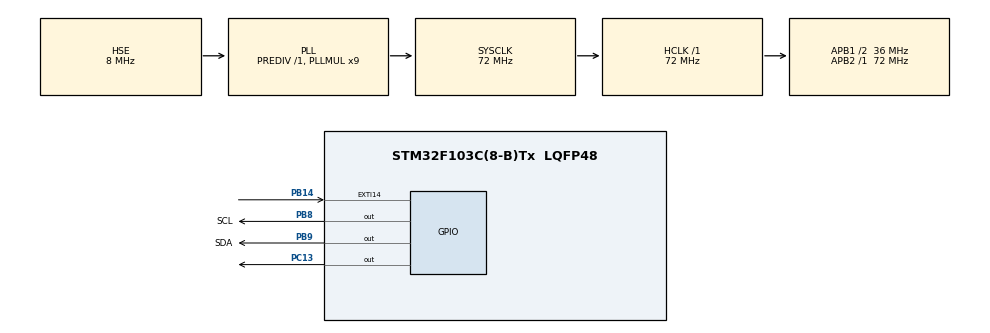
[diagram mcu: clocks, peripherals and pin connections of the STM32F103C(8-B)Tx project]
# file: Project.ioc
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Mcu.Family=STM32F1
Mcu.Name=STM32F103C(8-B)Tx
Mcu.Package=LQFP48
NVIC.EXTI15_10_IRQn=true\:1\:0\:true\:false\:true\:true\:true\:true
NVIC.PriorityGroup=NVIC_PRIORITYGROUP_4
PA13.Mode=Serial_Wire
PA13.Signal=SYS_JTMS-SWDIO
PA14.Mode=Serial_Wire
PA14.Signal=SYS_JTCK-SWCLK
PB14.GPIO_ModeDefaultEXTI=GPIO_MODE_IT_FALLING
PB14.GPIO_PuPd=GPIO_PULLUP
PB14.Signal=GPXTI14
PB8.GPIO_Label=SCL
PB8.GPIO_ModeDefaultOutputPP=GPIO_MODE_OUTPUT_OD
PB8.GPIO_PuPd=GPIO_NOPULL
PB8.GPIO_Speed=GPIO_SPEED_FREQ_HIGH
PB8.PinState=GPIO_PIN_RESET
PB8.Signal=GPIO_Output
PB9.GPIO_Label=SDA
PB9.GPIO_ModeDefaultOutputPP=GPIO_MODE_OUTPUT_OD
PB9.GPIO_PuPd=GPIO_NOPULL
PB9.GPIO_Speed=GPIO_SPEED_FREQ_HIGH
PB9.Signal=GPIO_Output
PC13-TAMPER-RTC.GPIO_PuPd=GPIO_PULLDOWN
PC13-TAMPER-RTC.Signal=GPIO_Output
PD0-OSC_IN.Mode=HSE-External-Oscillator
PD0-OSC_IN.Signal=RCC_OSC_IN
PD1-OSC_OUT.Mode=HSE-External-Oscillator
PD1-OSC_OUT.Signal=RCC_OSC_OUT
ProjectManager.HeapSize=0x200
ProjectManager.StackSize=0x400
ProjectManager.TargetToolchain=MDK-ARM V5.32
RCC.AHBFreq_Value=72000000
RCC.APB1CLKDivider=RCC_HCLK_DIV2
RCC.APB1Freq_Value=36000000
RCC.APB1TimFreq_Value=72000000
RCC.APB2Freq_Value=72000000
RCC.APB2TimFreq_Value=72000000
RCC.HCLKFreq_Value=72000000
RCC.PLLMUL=RCC_PLL_MUL9
RCC.PLLSourceVirtual=RCC_PLLSOURCE_HSE
RCC.SYSCLKFreq_VALUE=72000000
RCC.SYSCLKSource=RCC_SYSCLKSOURCE_PLLCLK
RCC.USBFreq_Value=72000000
board=custom

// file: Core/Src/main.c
/* USER CODE BEGIN Header */
/**
  ******************************************************************************
  * @file           : main.c
  * @brief          : Main program body
  ******************************************************************************
  * @attention
  *
  * Copyright (c) 2025 STMicroelectronics.
  * All rights reserved.
  *
  * This software is licensed under terms that can be found in the LICENSE file
  * in the root directory of this software component.
  * If no LICENSE file comes with this software, it is provided AS-IS.
  *
  ******************************************************************************
  */
/* USER CODE END Header */
#include "main.h"
#include "gpio.h"

/* USER CODE BEGIN Includes */
#include "OLED.h"
#include "CountSensor.h"
/* USER CODE END Includes */

void SystemClock_Config(void);

/* USER CODE BEGIN 0 */

// 滴答定时器中断回调函数
void HAL_SYSTICK_Callback(void)
{
    // 每500ms翻转一次PC13引脚的电平状态，实现LED闪烁效果
    if(uwTick % 500 == 0)
    {
        HAL_GPIO_TogglePin(GPIOC, GPIO_PIN_13);
    }
}

/* USER CODE END 0 */

int main(void)
{

  /* MCU Configuration--------------------------------------------------------*/

  /* Reset of all peripherals, Initializes the Flash interface and the Systick. */
  HAL_Init();

  /* Configure the system clock */
  SystemClock_Config();

  /* Initialize all configured peripherals */
  MX_GPIO_Init();
  /* USER CODE BEGIN 2 */

  /*模块初始化*/
  OLED_Init();			              //OLED初始化
  CountSensor_Init();		          //计数传感器初始化

  /*显示静态字符串*/
  OLED_ShowString(1, 1, "Count:");	  //1行1列显示字符串Count:

  /* USER CODE END 2 */

  /* Infinite loop */
  /* USER CODE BEGIN WHILE */
  while (1)
  {
    OLED_ShowNum(1, 7, CountSensor_Get(), 5);		//OLED不断刷新显示CountSensor_Get的返回值
    /* USER CODE END WHILE */

  }
}

void SystemClock_Config(void)
{
  RCC_OscInitTypeDef RCC_OscInitStruct = {0};
  RCC_ClkInitTypeDef RCC_ClkInitStruct = {0};

  /** Initializes the RCC Oscillators according to the specified parameters
  * in the RCC_OscInitTypeDef structure.
  */
  RCC_OscInitStruct.OscillatorType = RCC_OSCILLATORTYPE_HSE;
  RCC_OscInitStruct.HSEState = RCC_HSE_ON;
  RCC_OscInitStruct.HSEPredivValue = RCC_HSE_PREDIV_DIV1;
  RCC_OscInitStruct.HSIState = RCC_HSI_ON;
  RCC_OscInitStruct.PLL.PLLState = RCC_PLL_ON;
  RCC_OscInitStruct.PLL.PLLSource = RCC_PLLSOURCE_HSE;
  RCC_OscInitStruct.PLL.PLLMUL = RCC_PLL_MUL9;
  if (HAL_RCC_OscConfig(&RCC_OscInitStruct) != HAL_OK)
  {
    Error_Handler();
  }

  /** Initializes the CPU, AHB and APB buses clocks
  */
  RCC_ClkInitStruct.ClockType = RCC_CLOCKTYPE_HCLK|RCC_CLOCKTYPE_SYSCLK
                              |RCC_CLOCKTYPE_PCLK1|RCC_CLOCKTYPE_PCLK2;
  RCC_ClkInitStruct.SYSCLKSource = RCC_SYSCLKSOURCE_PLLCLK;
  RCC_ClkInitStruct.AHBCLKDivider = RCC_SYSCLK_DIV1;
  RCC_ClkInitStruct.APB1CLKDivider = RCC_HCLK_DIV2;
  RCC_ClkInitStruct.APB2CLKDivider = RCC_HCLK_DIV1;

  if (HAL_RCC_ClockConfig(&RCC_ClkInitStruct, FLASH_LATENCY_2) != HAL_OK)
  {
    Error_Handler();
  }
}

void Error_Handler(void)
{
  __disable_irq();
  while (1)
  {
  }
}
